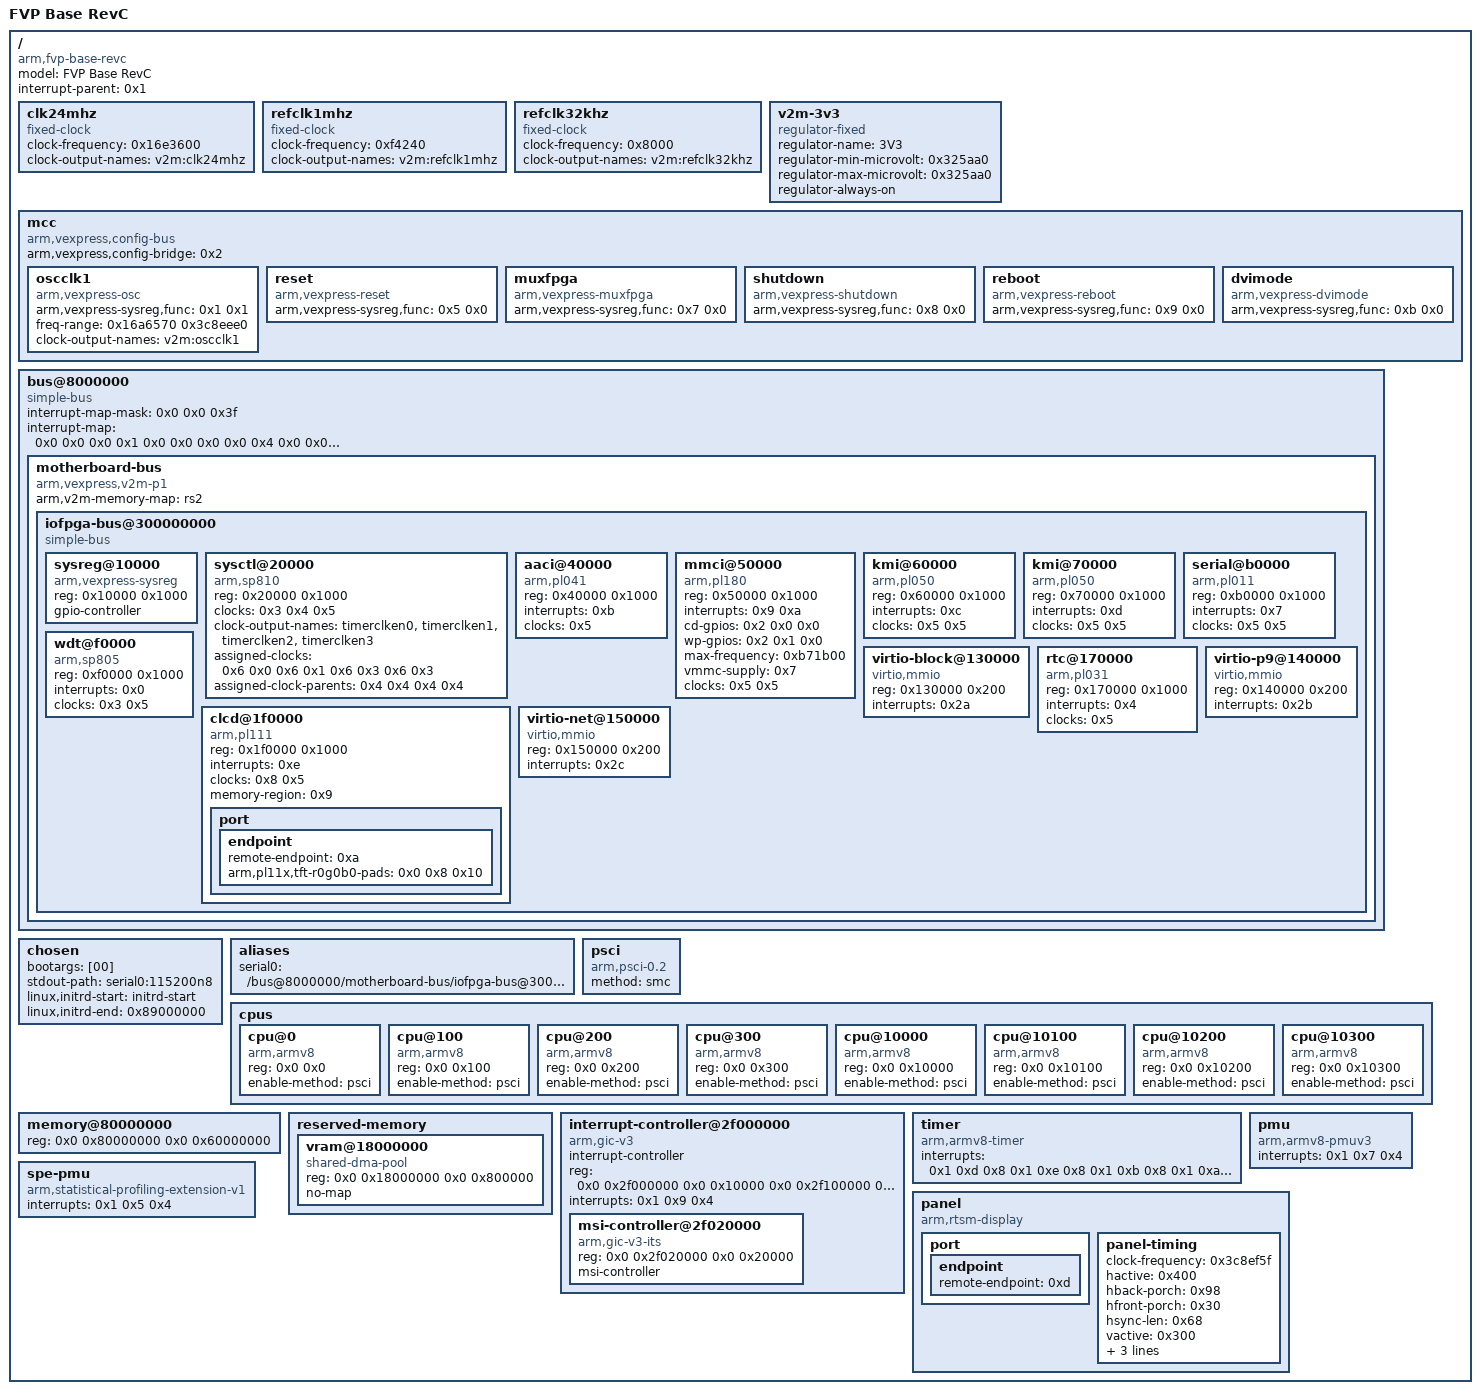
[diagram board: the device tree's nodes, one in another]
/dts-v1/;

/memreserve/	0x0000000080000000 0x0000000000010000;
/ {
	model = "FVP Base RevC";
	compatible = "arm,fvp-base-revc", "arm,vexpress";
	interrupt-parent = <0x1>;
	#address-cells = <0x2>;
	#size-cells = <0x2>;

	clk24mhz {
		compatible = "fixed-clock";
		#clock-cells = <0x0>;
		clock-frequency = <0x16e3600>;
		clock-output-names = "v2m:clk24mhz";
		linux,phandle = <0x5>;
		phandle = <0x5>;
	};

	refclk1mhz {
		compatible = "fixed-clock";
		#clock-cells = <0x0>;
		clock-frequency = <0xf4240>;
		clock-output-names = "v2m:refclk1mhz";
		linux,phandle = <0x4>;
		phandle = <0x4>;
	};

	refclk32khz {
		compatible = "fixed-clock";
		#clock-cells = <0x0>;
		clock-frequency = <0x8000>;
		clock-output-names = "v2m:refclk32khz";
		linux,phandle = <0x3>;
		phandle = <0x3>;
	};

	v2m-3v3 {
		compatible = "regulator-fixed";
		regulator-name = "3V3";
		regulator-min-microvolt = <0x325aa0>;
		regulator-max-microvolt = <0x325aa0>;
		regulator-always-on;
		linux,phandle = <0x7>;
		phandle = <0x7>;
	};

	mcc {
		compatible = "arm,vexpress,config-bus";
		arm,vexpress,config-bridge = <0x2>;

		oscclk1 {
			compatible = "arm,vexpress-osc";
			arm,vexpress-sysreg,func = <0x1 0x1>;
			freq-range = <0x16a6570 0x3c8eee0>;
			#clock-cells = <0x0>;
			clock-output-names = "v2m:oscclk1";
			linux,phandle = <0x8>;
			phandle = <0x8>;
		};

		reset {
			compatible = "arm,vexpress-reset";
			arm,vexpress-sysreg,func = <0x5 0x0>;
		};

		muxfpga {
			compatible = "arm,vexpress-muxfpga";
			arm,vexpress-sysreg,func = <0x7 0x0>;
		};

		shutdown {
			compatible = "arm,vexpress-shutdown";
			arm,vexpress-sysreg,func = <0x8 0x0>;
		};

		reboot {
			compatible = "arm,vexpress-reboot";
			arm,vexpress-sysreg,func = <0x9 0x0>;
		};

		dvimode {
			compatible = "arm,vexpress-dvimode";
			arm,vexpress-sysreg,func = <0xb 0x0>;
		};
	};

	bus@8000000 {
		compatible = "simple-bus";
		#address-cells = <0x2>;
		#size-cells = <0x1>;
		ranges = <0x0 0x0 0x0 0x8000000 0x4000000 0x1 0x0 0x0 0x14000000 0x4000000 0x2 0x0 0x0 0x18000000 0x4000000 0x3 0x0 0x0 0x1c000000 0x4000000 0x4 0x0 0x0 0xc000000 0x4000000 0x5 0x0 0x0 0x10000000 0x4000000>;
		#interrupt-cells = <0x1>;
		interrupt-map-mask = <0x0 0x0 0x3f>;
		interrupt-map = <0x0 0x0 0x0 0x1 0x0 0x0 0x0 0x0 0x4 0x0 0x0 0x1 0x1 0x0 0x0 0x0 0x1 0x4 0x0 0x0 0x2 0x1 0x0 0x0 0x0 0x2 0x4 0x0 0x0 0x3 0x1 0x0 0x0 0x0 0x3 0x4 0x0 0x0 0x4 0x1 0x0 0x0 0x0 0x4 0x4 0x0 0x0 0x5 0x1 0x0 0x0 0x0 0x5 0x4 0x0 0x0 0x6 0x1 0x0 0x0 0x0 0x6 0x4 0x0 0x0 0x7 0x1 0x0 0x0 0x0 0x7 0x4 0x0 0x0 0x8 0x1 0x0 0x0 0x0 0x8 0x4 0x0 0x0 0x9 0x1 0x0 0x0 0x0 0x9 0x4 0x0 0x0 0xa 0x1 0x0 0x0 0x0 0xa 0x4 0x0 0x0 0xb 0x1 0x0 0x0 0x0 0xb 0x4 0x0 0x0 0xc 0x1 0x0 0x0 0x0 0xc 0x4 0x0 0x0 0xd 0x1 0x0 0x0 0x0 0xd 0x4 0x0 0x0 0xe 0x1 0x0 0x0 0x0 0xe 0x4 0x0 0x0 0xf 0x1 0x0 0x0 0x0 0xf 0x4 0x0 0x0 0x10 0x1 0x0 0x0 0x0 0x10 0x4 0x0 0x0 0x11 0x1 0x0 0x0 0x0 0x11 0x4 0x0 0x0 0x12 0x1 0x0 0x0 0x0 0x12 0x4 0x0 0x0 0x13 0x1 0x0 0x0 0x0 0x13 0x4 0x0 0x0 0x14 0x1 0x0 0x0 0x0 0x14 0x4 0x0 0x0 0x15 0x1 0x0 0x0 0x0 0x15 0x4 0x0 0x0 0x16 0x1 0x0 0x0 0x0 0x16 0x4 0x0 0x0 0x17 0x1 0x0 0x0 0x0 0x17 0x4 0x0 0x0 0x18 0x1 0x0 0x0 0x0 0x18 0x4 0x0 0x0 0x19 0x1 0x0 0x0 0x0 0x19 0x4 0x0 0x0 0x1a 0x1 0x0 0x0 0x0 0x1a 0x4 0x0 0x0 0x1b 0x1 0x0 0x0 0x0 0x1b 0x4 0x0 0x0 0x1c 0x1 0x0 0x0 0x0 0x1c 0x4 0x0 0x0 0x1d 0x1 0x0 0x0 0x0 0x1d 0x4 0x0 0x0 0x1e 0x1 0x0 0x0 0x0 0x1e 0x4 0x0 0x0 0x1f 0x1 0x0 0x0 0x0 0x1f 0x4 0x0 0x0 0x20 0x1 0x0 0x0 0x0 0x20 0x4 0x0 0x0 0x21 0x1 0x0 0x0 0x0 0x21 0x4 0x0 0x0 0x22 0x1 0x0 0x0 0x0 0x22 0x4 0x0 0x0 0x23 0x1 0x0 0x0 0x0 0x23 0x4 0x0 0x0 0x24 0x1 0x0 0x0 0x0 0x24 0x4 0x0 0x0 0x25 0x1 0x0 0x0 0x0 0x25 0x4 0x0 0x0 0x26 0x1 0x0 0x0 0x0 0x26 0x4 0x0 0x0 0x27 0x1 0x0 0x0 0x0 0x27 0x4 0x0 0x0 0x28 0x1 0x0 0x0 0x0 0x28 0x4 0x0 0x0 0x29 0x1 0x0 0x0 0x0 0x29 0x4 0x0 0x0 0x2a 0x1 0x0 0x0 0x0 0x2a 0x4 0x0 0x0 0x2b 0x1 0x0 0x0 0x0 0x2b 0x4 0x0 0x0 0x2c 0x1 0x0 0x0 0x0 0x2c 0x4>;

		motherboard-bus {
			arm,v2m-memory-map = "rs2";
			compatible = "arm,vexpress,v2m-p1", "simple-bus";
			#address-cells = <0x2>;
			#size-cells = <0x1>;
			#interrupt-cells = <0x1>;
			ranges;

			iofpga-bus@300000000 {
				compatible = "simple-bus";
				#address-cells = <0x1>;
				#size-cells = <0x1>;
				ranges = <0x0 0x3 0x0 0x200000>;

				sysreg@10000 {
					compatible = "arm,vexpress-sysreg";
					reg = <0x10000 0x1000>;
					gpio-controller;
					#gpio-cells = <0x2>;
					linux,phandle = <0x2>;
					phandle = <0x2>;
				};

				sysctl@20000 {
					compatible = "arm,sp810", "arm,primecell";
					reg = <0x20000 0x1000>;
					clocks = <0x3 0x4 0x5>;
					clock-names = "refclk", "timclk", "apb_pclk";
					#clock-cells = <0x1>;
					clock-output-names = "timerclken0", "timerclken1", "timerclken2", "timerclken3";
					assigned-clocks = <0x6 0x0 0x6 0x1 0x6 0x3 0x6 0x3>;
					assigned-clock-parents = <0x4 0x4 0x4 0x4>;
					linux,phandle = <0x6>;
					phandle = <0x6>;
				};

				aaci@40000 {
					compatible = "arm,pl041", "arm,primecell";
					reg = <0x40000 0x1000>;
					interrupts = <0xb>;
					clocks = <0x5>;
					clock-names = "apb_pclk";
				};

				mmci@50000 {
					compatible = "arm,pl180", "arm,primecell";
					reg = <0x50000 0x1000>;
					interrupts = <0x9 0xa>;
					cd-gpios = <0x2 0x0 0x0>;
					wp-gpios = <0x2 0x1 0x0>;
					max-frequency = <0xb71b00>;
					vmmc-supply = <0x7>;
					clocks = <0x5 0x5>;
					clock-names = "mclk", "apb_pclk";
				};

				kmi@60000 {
					compatible = "arm,pl050", "arm,primecell";
					reg = <0x60000 0x1000>;
					interrupts = <0xc>;
					clocks = <0x5 0x5>;
					clock-names = "KMIREFCLK", "apb_pclk";
				};

				kmi@70000 {
					compatible = "arm,pl050", "arm,primecell";
					reg = <0x70000 0x1000>;
					interrupts = <0xd>;
					clocks = <0x5 0x5>;
					clock-names = "KMIREFCLK", "apb_pclk";
				};

				serial@b0000 {
					compatible = "arm,pl011", "arm,primecell";
					reg = <0xb0000 0x1000>;
					interrupts = <0x7>;
					clocks = <0x5 0x5>;
					clock-names = "uartclk", "apb_pclk";
				};

				wdt@f0000 {
					compatible = "arm,sp805", "arm,primecell";
					reg = <0xf0000 0x1000>;
					interrupts = <0x0>;
					clocks = <0x3 0x5>;
					clock-names = "wdog_clk", "apb_pclk";
				};

				virtio-block@130000 {
					compatible = "virtio,mmio";
					reg = <0x130000 0x200>;
					interrupts = <0x2a>;
				};

				rtc@170000 {
					compatible = "arm,pl031", "arm,primecell";
					reg = <0x170000 0x1000>;
					interrupts = <0x4>;
					clocks = <0x5>;
					clock-names = "apb_pclk";
				};

				clcd@1f0000 {
					compatible = "arm,pl111", "arm,primecell";
					reg = <0x1f0000 0x1000>;
					interrupt-names = "combined";
					interrupts = <0xe>;
					clocks = <0x8 0x5>;
					clock-names = "clcdclk", "apb_pclk";
					memory-region = <0x9>;

					port {

						endpoint {
							remote-endpoint = <0xa>;
							arm,pl11x,tft-r0g0b0-pads = <0x0 0x8 0x10>;
							linux,phandle = <0xd>;
							phandle = <0xd>;
						};
					};
				};

				virtio-p9@140000 {
					compatible = "virtio,mmio";
					reg = <0x140000 0x200>;
					interrupts = <0x2b>;
				};

				virtio-net@150000 {
					compatible = "virtio,mmio";
					reg = <0x150000 0x200>;
					interrupts = <0x2c>;
				};
			};
		};
	};

	chosen {
		bootargs = [00];
		stdout-path = "serial0:115200n8";
		linux,initrd-start = <initrd-start>;
		linux,initrd-end = <0x89000000>;
	};

	aliases {
		serial0 = "/bus@8000000/motherboard-bus/iofpga-bus@300000000/serial@b0000";
	};

	psci {
		compatible = "arm,psci-0.2";
		method = "smc";
	};

	cpus {
		#address-cells = <0x2>;
		#size-cells = <0x0>;

		cpu@0 {
			device_type = "cpu";
			compatible = "arm,armv8";
			reg = <0x0 0x0>;
			enable-method = "psci";
		};

		cpu@100 {
			device_type = "cpu";
			compatible = "arm,armv8";
			reg = <0x0 0x100>;
			enable-method = "psci";
		};

		cpu@200 {
			device_type = "cpu";
			compatible = "arm,armv8";
			reg = <0x0 0x200>;
			enable-method = "psci";
		};

		cpu@300 {
			device_type = "cpu";
			compatible = "arm,armv8";
			reg = <0x0 0x300>;
			enable-method = "psci";
		};

		cpu@10000 {
			device_type = "cpu";
			compatible = "arm,armv8";
			reg = <0x0 0x10000>;
			enable-method = "psci";
		};

		cpu@10100 {
			device_type = "cpu";
			compatible = "arm,armv8";
			reg = <0x0 0x10100>;
			enable-method = "psci";
		};

		cpu@10200 {
			device_type = "cpu";
			compatible = "arm,armv8";
			reg = <0x0 0x10200>;
			enable-method = "psci";
		};

		cpu@10300 {
			device_type = "cpu";
			compatible = "arm,armv8";
			reg = <0x0 0x10300>;
			enable-method = "psci";
		};
	};

	memory@80000000 {
		device_type = "memory";
		reg = <0x0 0x80000000 0x0 0x60000000>;
	};

	reserved-memory {
		#address-cells = <0x2>;
		#size-cells = <0x2>;
		ranges;
		
		vram@18000000 {
			compatible = "shared-dma-pool";
			reg = <0x0 0x18000000 0x0 0x800000>;
			no-map;
			linux,phandle = <0x9>;
			phandle = <0x9>;
		};
	};

	interrupt-controller@2f000000 {
		compatible = "arm,gic-v3";
		#interrupt-cells = <0x3>;
		#address-cells = <0x2>;
		#size-cells = <0x2>;
		ranges;
		interrupt-controller;
		reg = <0x0 0x2f000000 0x0 0x10000 0x0 0x2f100000 0x0 0x200000 0x0 0x2c000000 0x0 0x2000 0x0 0x2c010000 0x0 0x2000 0x0 0x2c02f000 0x0 0x2000>;
		interrupts = <0x1 0x9 0x4>;
		linux,phandle = <0x1>;
		phandle = <0x1>;

		msi-controller@2f020000 {
			#msi-cells = <0x1>;
			compatible = "arm,gic-v3-its";
			reg = <0x0 0x2f020000 0x0 0x20000>;
			msi-controller;
			linux,phandle = <0xb>;
			phandle = <0xb>;
		};
	};

	timer {
		compatible = "arm,armv8-timer";
		interrupts = <0x1 0xd 0x8 0x1 0xe 0x8 0x1 0xb 0x8 0x1 0xa 0x8>;
	};
	
	pmu {
		compatible = "arm,armv8-pmuv3";
		interrupts = <0x1 0x7 0x4>;
	};

	spe-pmu {
		compatible = "arm,statistical-profiling-extension-v1";
		interrupts = <0x1 0x5 0x4>;
	};

	panel {
		compatible = "arm,rtsm-display", "panel-dpi";

		port {

			endpoint {
				remote-endpoint = <0xd>;
				linux,phandle = <0xa>;
				phandle = <0xa>;
			};
		};

		panel-timing {
			clock-frequency = <0x3c8ef5f>;
			hactive = <0x400>;
			hback-porch = <0x98>;
			hfront-porch = <0x30>;
			hsync-len = <0x68>;
			vactive = <0x300>;
			vback-porch = <0x17>;
			vfront-porch = <0x3>;
			vsync-len = <0x4>;
		};
	};
	
};
